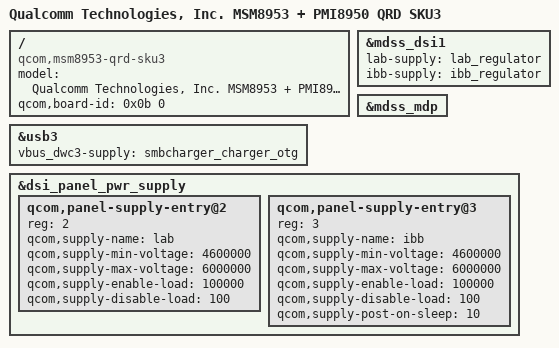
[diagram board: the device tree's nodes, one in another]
/*
 * Copyright (c) 2015-2017, The Linux Foundation. All rights reserved.
 *
 * This program is free software; you can redistribute it and/or modify
 * it under the terms of the GNU General Public License version 2 and
 * only version 2 as published by the Free Software Foundation.
 *
 * This program is distributed in the hope that it will be useful,
 * but WITHOUT ANY WARRANTY; without even the implied warranty of
 * MERCHANTABILITY or FITNESS FOR A PARTICULAR PURPOSE.  See the
 * GNU General Public License for more details.
 */

/dts-v1/;

#include "msm8953.dtsi"
#include "msm-pmi8950.dtsi"

/ {
	model = "Qualcomm Technologies, Inc. MSM8953 + PMI8950 QRD SKU3";
	compatible = "qcom,msm8953-qrd-sku3",
		   "qcom,msm8953-qrd", "qcom,msm8953", "qcom,qrd";
	qcom,board-id= <0x0b 0>;
};

#include "msm8953-qrd-sku3.dtsi"

&usb3 {
	vbus_dwc3-supply = <&smbcharger_charger_otg>;
};

&mdss_dsi1 {
	lab-supply = <&lab_regulator>;
	ibb-supply = <&ibb_regulator>;
};

&mdss_mdp {
	/delete-node/ qcom,mdss_dsi_sim_video;
	/delete-node/ qcom,mdss_dsi_dual_sim_video;
	/delete-node/ qcom,mdss_dsi_sim_cmd;
	/delete-node/ qcom,mdss_dsi_dual_sim_cmd;
	/delete-node/ qcom,mdss_dsi_truly_1080p_video;
	/delete-node/ qcom,mdss_dsi_truly_1080p_cmd;
	/delete-node/ qcom,mdss_dsi_adv7533_1080p;
	/delete-node/ qcom,mdss_dsi_adv7533_720p;
	/delete-node/ qcom,mdss_dsi_r69006_1080p_video;
	/delete-node/ qcom,mdss_dsi_r69006_1080p_cmd;
	/delete-node/ qcom,mdss_dsi_truly_wuxga_video;
	/delete-node/ qcom,mdss_dsi_lt8912_480p_video;
	/delete-node/ qcom,mdss_dsi_lt8912_1080p_video;
	/delete-node/ qcom,mdss_dsi_lgd_incell_sw49106_fhd_video;
	/delete-node/ qcom,mdss_dsi_boyi_hx83100a_800p_video;
};

&dsi_panel_pwr_supply {
	qcom,panel-supply-entry@2 {
		reg = <2>;
		qcom,supply-name = "lab";
		qcom,supply-min-voltage = <4600000>;
		qcom,supply-max-voltage = <6000000>;
		qcom,supply-enable-load = <100000>;
		qcom,supply-disable-load = <100>;
	};

	qcom,panel-supply-entry@3 {
		reg = <3>;
		qcom,supply-name = "ibb";
		qcom,supply-min-voltage = <4600000>;
		qcom,supply-max-voltage = <6000000>;
		qcom,supply-enable-load = <100000>;
		qcom,supply-disable-load = <100>;
		qcom,supply-post-on-sleep = <10>;
	};
};

#include "m1721/msm8953-m1721.dtsi"
